# LPC5516 register map
Vendor: nxp.com; File version: 1.0
CPU: CM33 r2p0, little endian, MPU, FPU, VTOR, 3 interrupt priority bits
Registers are 32-bit, read-write, reset 0x0 unless marked. A register's access mark holds for its fields unless they carry their own. Offsets are from the block's base; [hi:lo] are bit positions.

## FLEXCOMM0 — Flexcomm serial communication
Base 0x40086000
Same registers: FLEXCOMM1 0x40087000, FLEXCOMM2 0x40088000, FLEXCOMM3 0x40089000, FLEXCOMM4 0x4008A000, FLEXCOMM5 0x40096000, FLEXCOMM6 0x40097000, FLEXCOMM7 0x40098000, FLEXCOMM8 0x4009F000
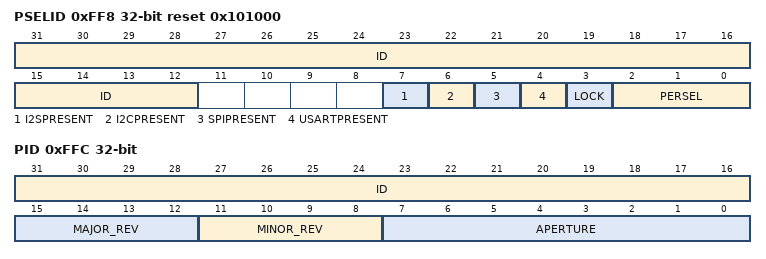
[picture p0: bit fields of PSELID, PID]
0xFF8 PSELID reset 0x101000 — Peripheral Select and Flexcomm ID register.
  [31:12] ID ro — Flexcomm ID.
  [7] I2SPRESENT ro — I 2S present indicator. This field is Read-only.
    0=NOT_PRESENT (This Flexcomm does not include the I2S function.); 1=PRESENT (This Flexcomm includes the I2S function.)
  [6] I2CPRESENT ro — I2C present indicator. This field is Read-only.
    0=NOT_PRESENT (This Flexcomm does not include the I2C function.); 1=PRESENT (This Flexcomm includes the I2C function.)
  [5] SPIPRESENT ro — SPI present indicator. This field is Read-only.
    0=NOT_PRESENT (This Flexcomm does not include the SPI function.); 1=PRESENT (This Flexcomm includes the SPI function.)
  [4] USARTPRESENT ro — USART present indicator. This field is Read-only.
    0=NOT_PRESENT (This Flexcomm does not include the USART function.); 1=PRESENT (This Flexcomm includes the USART function.)
  [3] LOCK — Lock the peripheral select. This field is writable by software.
    0=UNLOCKED (Peripheral select can be changed by software.); 1=LOCKED (Peripheral select is locked and cannot be changed until this Flexcomm or the entire device is reset.)
  [2:0] PERSEL — Peripheral Select. This field is writable by software.
    0=NO_PERIPH_SELECTED (No peripheral selected.); 1=USART (USART function selected.); 2=SPI (SPI function selected.); 3=I2C (I2C function selected.); 4=I2S_TRANSMIT (I2S transmit function selected.); 5=I2S_RECEIVE (I2S receive function selected.)
0xFFC PID ro — Peripheral identification register.
  [31:16] ID — Module identifier for the selected function.
  [15:12] MAJOR_REV — Major revision of module implementation.
  [11:8] MINOR_REV — Minor revision of module implementation.
  [7:0] APERTURE — size aperture for the register port on the bus (APB or AHB).

## CRC_ENGINE
Base 0x40095000
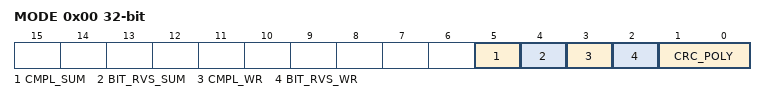
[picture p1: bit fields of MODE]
0x00 MODE — CRC mode register
  [5] CMPL_SUM — CRC sum complement: 1 = 1's complement for CRC_SUM 0 = No 1's complement for CRC_SUM
  [4] BIT_RVS_SUM — CRC sum bit order: 1 = Bit order reverse for CRC_SUM 0 = No bit order reverse for CRC_SUM
  [3] CMPL_WR — Data complement: 1 = 1's complement for CRC_WR_DATA 0 = No 1's complement for CRC_WR_DATA
  [2] BIT_RVS_WR — Data bit order: 1 = Bit order reverse for CRC_WR_DATA (per byte) 0 = No bit order reverse for CRC_WR_DATA (per byte)
  [1:0] CRC_POLY — CRC polynomial: 1X = CRC-32 polynomial 01 = CRC-16 polynomial 00 = CRC-CCITT polynomial
0x04 SEED reset 0xFFFF — CRC seed register
  [31:0] CRC_SEED — A write access to this register will load CRC seed value to CRC_SUM register with selected bit order and 1's complement pre-processes. A write access to this register will overrule the CRC calculation in progresses.
0x08 SUM ro reset 0xFFFF (SUM_WR_DATA view) — CRC checksum register
  [31:0] CRC_SUM — The most recent CRC sum can be read through this register with selected bit order and 1's complement post-processes.
0x08 WR_DATA wo reset not defined (SUM_WR_DATA view) — CRC data register
  [31:0] CRC_WR_DATA — Data written to this register will be taken to perform CRC calculation with selected bit order and 1's complement pre-process. Any write size 8, 16 or 32-bit are allowed and accept back-to-back transactions.

## DBGMAILBOX — MCU Debugger Mailbox
Base 0x4009C000
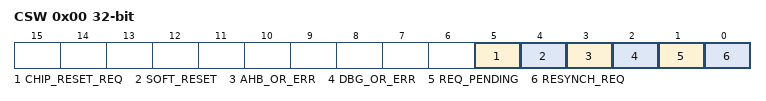
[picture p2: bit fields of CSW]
0x00 CSW — CRC mode register
  [5] CHIP_RESET_REQ wo — Write only bit. Once written will cause the chip to reset (note that the DM is not reset by this reset as it is only resettable by a SOFT reset or a POR/BOD event)
  [4] SOFT_RESET — Soft Reset for DM (write-only from AHB, not readable and selfclearing). A write to this bit will cause a soft reset for DM.
  [3] AHB_OR_ERR — AHB overrun Error (Return value overwritten by ROM)
  [2] DBG_OR_ERR — Debugger overrun error (previous REQUEST overwritten before being picked up by ROM)
  [1] REQ_PENDING — Request is pending from debugger (i.e unread value in REQUEST)
  [0] RESYNCH_REQ — Debugger will set this bit to 1 to request a resynchronrisation
0x04 REQUEST reset 0xFFFF — CRC seed register
  [31:0] REQ — Request Value
0x08 RETURN — Return value from ROM.
  [31:0] RET — The Return value from ROM.
0xFC ID ro reset 0x2A0000 — Identification register
  [31:0] ID — Identification value.

## CDOG
Base 0x400A1000
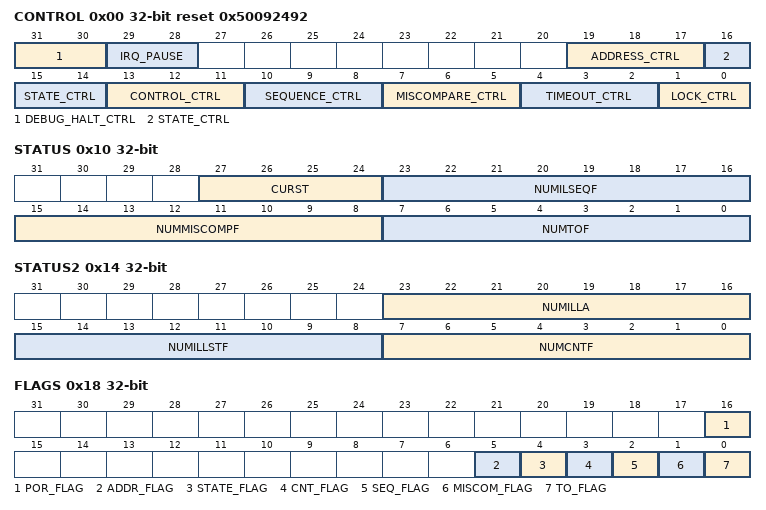
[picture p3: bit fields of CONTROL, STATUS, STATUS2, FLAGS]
0x00 CONTROL reset 0x50092492 — The control fields, which constitute CONTROL, control all controllable attributes of the module, including those of CONTROL itself.
  [31:30] DEBUG_HALT_CTRL — DEBUG_HALT control field
  [29:28] IRQ_PAUSE — IRQ pause control field
  [19:17] ADDRESS_CTRL — ADDRESS control field
  [16:14] STATE_CTRL — STATE control field
  [13:11] CONTROL_CTRL — CONTROL control field
  [10:8] SEQUENCE_CTRL — SEQUENCE control field
  [7:5] MISCOMPARE_CTRL — MISCOMPARE control field
  [4:2] TIMEOUT_CTRL — TIMEOUT control
  [1:0] LOCK_CTRL — Lock control field
0x04 RELOAD reset 0xFFFFFFFF — Instruction timer reload
  [31:0] RLOAD — Inst. Timer reload value
0x08 INSTRUCTION_TIMER reset 0xFFFFFFFF — The INSTRUCTION TIMER itself
  [31:0] INSTIM — INSTRUCTION TIMER 32-bit value
0x0C SECURE_COUNTER — Also known as SEC _CNT
  [31:0] SECCNT — Secure Counter
0x10 STATUS ro — Status register (1 of 2)
  [27:24] CURST — Current State
  [23:16] NUMILSEQF — Number of illegal sequence faults
  [15:8] NUMMISCOMPF — Number of Miscompare Faults
  [7:0] NUMTOF — Number of Timeout Faults
0x14 STATUS2 ro — STATUS register (2 of 2)
  [23:16] NUMILLA — Number of (illegal) address faults
  [15:8] NUMILLSTF — Number (of) state faults
  [7:0] NUMCNTF — Number (of) control faults
0x18 FLAGS — Hardware flags
  [16] POR_FLAG — Power-on reset flag
  [5] ADDR_FLAG — Address flag
  [4] STATE_FLAG
  [3] CNT_FLAG — Control (fault) flag
  [2] SEQ_FLAG — Sequence flag
  [1] MISCOM_FLAG — Miscompare flag
  [0] TO_FLAG — Timeout flag
0x1C PERSISTENT — Persistent (Ad. Hoc., quasi-NV) data storage
  [31:0] PERSIS — 32 regs free for user SW to enjoy
0x20 START wo — Write address for issuing the START command.
  [31:0] STRT — Address of start command access
0x24 STOP wo — Write address for issuing the STOP command.
  [31:0] STP — Address of stop command access
0x28 RESTART wo — Write address for issuing the RESTART command.
  [31:0] RSTRT
0x2C ADD wo — Write address for issuing the ADD command.
  [31:0] AD — Address of ADD command
0x30 ADD1 wo — Write address for issuing the ADD1 command.
  [31:0] AD1 — Address of ADD1 command.
0x34 ADD16 wo — Write address for issuing the ADD16 command.
  [31:0] AD16 — Address of ADD16
0x38 ADD256 wo — Write address for issuing the ADD16 command.
  [31:0] AD256 — Address of ADD256 command
0x3C SUB wo — Write address for issuing the SUB command.
  [31:0] S0B — Address of SUB command.
0x40 SUB1 wo — Write address for issuing the SUB1 command.
  [31:0] S1B — Address of SUB1 command.
0x44 SUB16 wo — Write address for issuing the SUB16 command.
  [31:0] SB16 — Address of SUB16 command.
0x48 SUB256 wo — Write address for issuing the SUB256 command.
  [31:0] SB256 — Address of (you guessed it) SUB256 command.

## Notices in the file
Copyright 2016-2019 NXP
All rights reserved.
SPDX-License-Identifier: BSD-3-Clause
